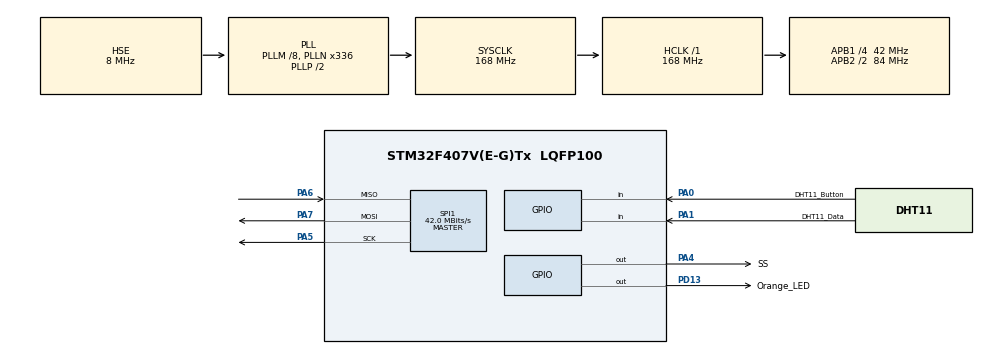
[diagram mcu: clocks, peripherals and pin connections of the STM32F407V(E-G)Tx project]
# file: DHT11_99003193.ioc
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Mcu.Family=STM32F4
Mcu.Name=STM32F407V(E-G)Tx
Mcu.Package=LQFP100
NVIC.PriorityGroup=NVIC_PRIORITYGROUP_0
PA0-WKUP.GPIO_Label=DHT11_Button
PA0-WKUP.Signal=GPIO_Input
PA1.GPIO_Label=DHT11_Data
PA1.Signal=GPIO_Input
PA13.Mode=Serial_Wire
PA13.Signal=SYS_JTMS-SWDIO
PA14.Mode=Serial_Wire
PA14.Signal=SYS_JTCK-SWCLK
PA4.GPIO_Label=SS
PA4.Signal=GPIO_Output
PA5.Mode=Full_Duplex_Master
PA5.Signal=SPI1_SCK
PA6.Mode=Full_Duplex_Master
PA6.Signal=SPI1_MISO
PA7.Mode=Full_Duplex_Master
PA7.Signal=SPI1_MOSI
PD13.GPIO_Label=Orange_LED
PD13.Signal=GPIO_Output
PH0-OSC_IN.Mode=HSE-External-Oscillator
PH0-OSC_IN.Signal=RCC_OSC_IN
PH1-OSC_OUT.Mode=HSE-External-Oscillator
PH1-OSC_OUT.Signal=RCC_OSC_OUT
ProjectManager.HeapSize=0x200
ProjectManager.StackSize=0x400
ProjectManager.TargetToolchain=STM32CubeIDE
RCC.48MHZClocksFreq_Value=48000000
RCC.AHBFreq_Value=168000000
RCC.APB1CLKDivider=RCC_HCLK_DIV4
RCC.APB1Freq_Value=42000000
RCC.APB1TimFreq_Value=84000000
RCC.APB2CLKDivider=RCC_HCLK_DIV2
RCC.APB2Freq_Value=84000000
RCC.APB2TimFreq_Value=168000000
RCC.CortexFreq_Value=168000000
RCC.HCLKFreq_Value=168000000
RCC.HSE_VALUE=8000000
RCC.HSI_VALUE=16000000
RCC.PLLM=8
RCC.PLLN=336
RCC.PLLQ=7
RCC.PLLSourceVirtual=RCC_PLLSOURCE_HSE
RCC.SYSCLKFreq_VALUE=168000000
RCC.SYSCLKSource=RCC_SYSCLKSOURCE_PLLCLK
RCC.VCOOutputFreq_Value=336000000
SPI1.CalculateBaudRate=42.0 MBits/s
SPI1.Direction=SPI_DIRECTION_2LINES
SPI1.Mode=SPI_MODE_MASTER
SPI1.VirtualType=VM_MASTER
board=STM32F407G-DISC1

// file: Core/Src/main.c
/* USER CODE BEGIN Header */
/**
  ******************************************************************************
  * @file           : main.c
  * @brief          : Main program body
  ******************************************************************************
  * @attention
  *
  * <h2><center>&copy; Copyright (c) 2021 STMicroelectronics.
  * All rights reserved.</center></h2>
  *
  * This software component is licensed by ST under Ultimate Liberty license
  * SLA0044, the "License"; You may not use this file except in compliance with
  * the License. You may obtain a copy of the License at:
  *                             www.st.com/SLA0044
  *
  ******************************************************************************
  */
/* USER CODE END Header */
#include "main.h"

SPI_HandleTypeDef hspi1;

void SystemClock_Config(void);
static void MX_GPIO_Init(void);
static void MX_SPI1_Init(void);

int main(void)
{

  /* MCU Configuration--------------------------------------------------------*/

  /* Reset of all peripherals, Initializes the Flash interface and the Systick. */
  HAL_Init();

  /* Configure the system clock */
  SystemClock_Config();

  /* Initialize all configured peripherals */
  MX_GPIO_Init();
  MX_SPI1_Init();
  int8_t DHT11_Data_Read (void)
        {
        uint8_t p,r;
        for (r=0;r<8;r++)
        {
       if (!(HAL_GPIO_ReadPin (DHT11_Data_GPIO_Port, DHT11_Data_Pin)))
         {
         p&= ~(1<<(7-r));
         }
         else
         {
         p|= (1<<(7-r));
         }
        }
        return p;
        }

        uint8_t DHT11_TempA;
      //  volatile uint8_t DHT11_TempB;

      /* Infinite loop */
      /* USER CODE BEGIN WHILE */
      while(1)
      {
      HAL_GPIO_WritePin(SS_GPIO_Port, SS_Pin, DISABLE);
      if(HAL_GPIO_ReadPin(DHT11_Button_GPIO_Port, DHT11_Button_Pin) == 1) {

            DHT11_TempA = DHT11_Data_Read();
         //   DHT11_TempB = DHT11_Data_Read();

            if(DHT11_TempA)
            {
            HAL_GPIO_WritePin(Orange_LED_GPIO_Port, Orange_LED_Pin,1);
            HAL_Delay(50);
            }

            /*else
            {
            HAL_GPIO_WritePin(ORANGE_GPIO_Port, ORANGE_Pin, 1);
            HAL_Delay(50);
            }*/
            HAL_SPI_Transmit(&hspi1, &DHT11_TempA, 1, 10);

      }
      }
      /* USER CODE END WHILE */

      /* USER CODE BEGIN 3 */

}

/*
  * @brief System Clock Configuration
  * @retval None
  */
void SystemClock_Config(void)
{
  RCC_OscInitTypeDef RCC_OscInitStruct = {0};
  RCC_ClkInitTypeDef RCC_ClkInitStruct = {0};

  /** Configure the main internal regulator output voltage
  */
  __HAL_RCC_PWR_CLK_ENABLE();
  __HAL_PWR_VOLTAGESCALING_CONFIG(PWR_REGULATOR_VOLTAGE_SCALE1);
  /** Initializes the RCC Oscillators according to the specified parameters
  * in the RCC_OscInitTypeDef structure.
  */
  RCC_OscInitStruct.OscillatorType = RCC_OSCILLATORTYPE_HSE;
  RCC_OscInitStruct.HSEState = RCC_HSE_ON;
  RCC_OscInitStruct.PLL.PLLState = RCC_PLL_ON;
  RCC_OscInitStruct.PLL.PLLSource = RCC_PLLSOURCE_HSE;
  RCC_OscInitStruct.PLL.PLLM = 8;
  RCC_OscInitStruct.PLL.PLLN = 336;
  RCC_OscInitStruct.PLL.PLLP = RCC_PLLP_DIV2;
  RCC_OscInitStruct.PLL.PLLQ = 7;
  if (HAL_RCC_OscConfig(&RCC_OscInitStruct) != HAL_OK)
  {
    Error_Handler();
  }
  /** Initializes the CPU, AHB and APB buses clocks
  */
  RCC_ClkInitStruct.ClockType = RCC_CLOCKTYPE_HCLK|RCC_CLOCKTYPE_SYSCLK
                              |RCC_CLOCKTYPE_PCLK1|RCC_CLOCKTYPE_PCLK2;
  RCC_ClkInitStruct.SYSCLKSource = RCC_SYSCLKSOURCE_PLLCLK;
  RCC_ClkInitStruct.AHBCLKDivider = RCC_SYSCLK_DIV1;
  RCC_ClkInitStruct.APB1CLKDivider = RCC_HCLK_DIV4;
  RCC_ClkInitStruct.APB2CLKDivider = RCC_HCLK_DIV2;

  if (HAL_RCC_ClockConfig(&RCC_ClkInitStruct, FLASH_LATENCY_5) != HAL_OK)
  {
    Error_Handler();
  }
}

static void MX_SPI1_Init(void)
{

  /* SPI1 parameter configuration*/
  hspi1.Instance = SPI1;
  hspi1.Init.Mode = SPI_MODE_MASTER;
  hspi1.Init.Direction = SPI_DIRECTION_2LINES;
  hspi1.Init.DataSize = SPI_DATASIZE_8BIT;
  hspi1.Init.CLKPolarity = SPI_POLARITY_LOW;
  hspi1.Init.CLKPhase = SPI_PHASE_1EDGE;
  hspi1.Init.NSS = SPI_NSS_SOFT;
  hspi1.Init.BaudRatePrescaler = SPI_BAUDRATEPRESCALER_2;
  hspi1.Init.FirstBit = SPI_FIRSTBIT_MSB;
  hspi1.Init.TIMode = SPI_TIMODE_DISABLE;
  hspi1.Init.CRCCalculation = SPI_CRCCALCULATION_DISABLE;
  hspi1.Init.CRCPolynomial = 10;
  if (HAL_SPI_Init(&hspi1) != HAL_OK)
  {
    Error_Handler();
  }

}

static void MX_GPIO_Init(void)
{
  GPIO_InitTypeDef GPIO_InitStruct = {0};

  /* GPIO Ports Clock Enable */
  __HAL_RCC_GPIOH_CLK_ENABLE();
  __HAL_RCC_GPIOA_CLK_ENABLE();
  __HAL_RCC_GPIOD_CLK_ENABLE();

  /*Configure GPIO pin Output Level */
  HAL_GPIO_WritePin(SS_GPIO_Port, SS_Pin, GPIO_PIN_RESET);

  /*Configure GPIO pin Output Level */
  HAL_GPIO_WritePin(Orange_LED_GPIO_Port, Orange_LED_Pin, GPIO_PIN_RESET);

  /*Configure GPIO pins : DHT11_Button_Pin DHT11_Data_Pin */
  GPIO_InitStruct.Pin = DHT11_Button_Pin|DHT11_Data_Pin;
  GPIO_InitStruct.Mode = GPIO_MODE_INPUT;
  GPIO_InitStruct.Pull = GPIO_NOPULL;
  HAL_GPIO_Init(GPIOA, &GPIO_InitStruct);

  /*Configure GPIO pin : SS_Pin */
  GPIO_InitStruct.Pin = SS_Pin;
  GPIO_InitStruct.Mode = GPIO_MODE_OUTPUT_PP;
  GPIO_InitStruct.Pull = GPIO_NOPULL;
  GPIO_InitStruct.Speed = GPIO_SPEED_FREQ_LOW;
  HAL_GPIO_Init(SS_GPIO_Port, &GPIO_InitStruct);

  /*Configure GPIO pin : Orange_LED_Pin */
  GPIO_InitStruct.Pin = Orange_LED_Pin;
  GPIO_InitStruct.Mode = GPIO_MODE_OUTPUT_PP;
  GPIO_InitStruct.Pull = GPIO_NOPULL;
  GPIO_InitStruct.Speed = GPIO_SPEED_FREQ_LOW;
  HAL_GPIO_Init(Orange_LED_GPIO_Port, &GPIO_InitStruct);

}

void Error_Handler(void)
{
  __disable_irq();
  while (1)
  {
  }
}

/************************ (C) COPYRIGHT STMicroelectronics *****END OF FILE****/
